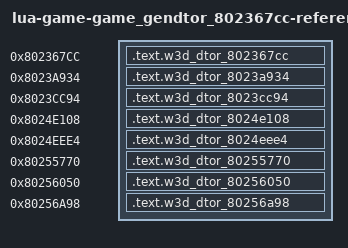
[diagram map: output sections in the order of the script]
/* Generated reference-only placements. All bodies are source-built. */
OUTPUT_FORMAT("elf32-powerpc")
OUTPUT_ARCH(powerpc)
ENTRY(w3d_dtor_802367cc)
_SDA_BASE_ = 0x804b2540;
_SDA2_BASE_ = 0x804c2540;
fn_801b4ef0 = 0x801b4ef0;
fn_801ea138 = 0x801ea138;
fn_801ea740 = 0x801ea740;
fn_8020803c = 0x8020803c;
fn_8020c5c4 = 0x8020c5c4;
fn_8023b5f0 = 0x8023b5f0;
fn_802523b4 = 0x802523b4;
fn_8025518c = 0x8025518c;
fn_80341588 = 0x80341588;
w3d_vtable_8041a810 = 0x8041a810;
w3d_vtable_8041ac48 = 0x8041ac48;
w3d_vtable_8041ae50 = 0x8041ae50;
w3d_vtable_8041b780 = 0x8041b780;
w3d_vtable_8041b7d0 = 0x8041b7d0;
w3d_vtable_8041b9c8 = 0x8041b9c8;
w3d_vtable_8041b9f0 = 0x8041b9f0;
w3d_vtable_8041ba18 = 0x8041ba18;
SECTIONS {
  .text.w3d_dtor_802367cc 0x802367cc : { *(.text.w3d_dtor_802367cc) }
  .text.w3d_dtor_8023a934 0x8023a934 : { *(.text.w3d_dtor_8023a934) }
  .text.w3d_dtor_8023cc94 0x8023cc94 : { *(.text.w3d_dtor_8023cc94) }
  .text.w3d_dtor_8024e108 0x8024e108 : { *(.text.w3d_dtor_8024e108) }
  .text.w3d_dtor_8024eee4 0x8024eee4 : { *(.text.w3d_dtor_8024eee4) }
  .text.w3d_dtor_80255770 0x80255770 : { *(.text.w3d_dtor_80255770) }
  .text.w3d_dtor_80256050 0x80256050 : { *(.text.w3d_dtor_80256050) }
  .text.w3d_dtor_80256a98 0x80256a98 : { *(.text.w3d_dtor_80256a98) }
  /DISCARD/ : { *(.text*) *(.rodata*) *(.data*) *(.bss*) *(.sdata*) *(.sbss*) *(.comment) }
}
